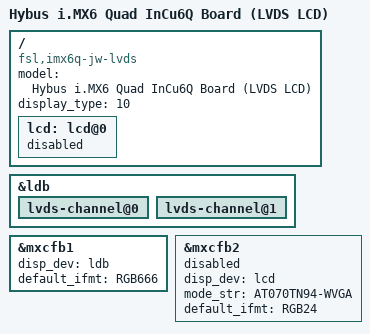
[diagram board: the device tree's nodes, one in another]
// SPDX-License-Identifier: GPL-2.0+
//
// Copyright 2012 Freescale Semiconductor, Inc.
// Copyright 2011 Linaro Ltd.

/dts-v1/;

#include "imx6q.dtsi"
#include "imx6qdl-JW-incu6.dtsi"

/ {
        model = "Hybus i.MX6 Quad InCu6Q Board (LVDS LCD)";
        compatible = "fsl,imx6q-jw-lvds", "fsl,imx6q";
        display_type = <10>;
        lcd: lcd@0 {
        //status = "okay";
        status = "disabled";
    };
};

&ldb {
    status = "okay";
        lvds-channel@0 {
        };

        lvds-channel@1 {
        status = "okay";
        };
};

&lcd {
    status = "disabled";
};

&mxcfb1 {
        disp_dev = "ldb";
    default_ifmt = "RGB666";
    //default_ifmt = "RGB24";
    //default_bpp = <32>;
    status = "okay";
};

&mxcfb2 {
        disp_dev = "lcd";
    mode_str ="AT070TN94-WVGA";
    default_ifmt = "RGB24";
    status = "disabled";
};
